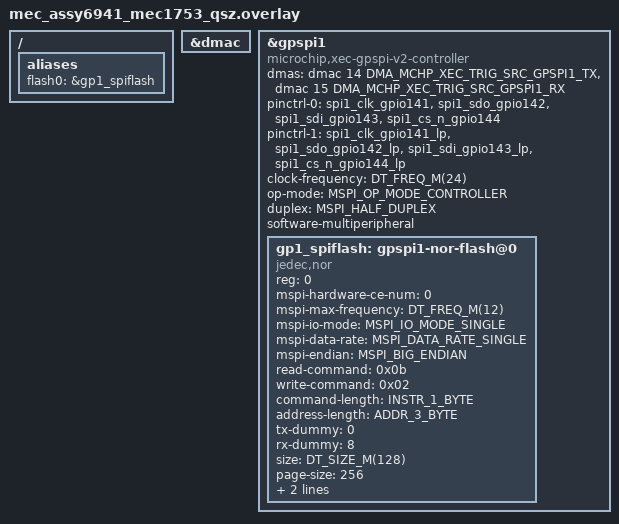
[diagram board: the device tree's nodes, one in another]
/*
 * Copyright (c) 2026 Microchip Technology Inc.
 *
 * SPDX-License-Identifier: Apache-2.0
 */

#include <zephyr/dt-bindings/dma/mchp-xec-dmac.h>

/* mec_assy6941 EVB with MEC1753 daughter card.
 * Winbond 25Q128JVSM +3.3V installed in socket U7
 * U7-5 SPI1_MOSI
 * U7-2 SPI1_MISO
 * U7-6 SPI1_CLK
 * U7-1 SPI1_nCS
 *
 * Jumper block JP20 3x4
 * 2-3 ON choose SPI1_nCS
 * 5-6 ON choose SPI1_MIS0
 * 8-9 ON choose SPI1_CLK
 * 11-12 ON choose SPI1_MOSI
 *
 * Header J37 1x6
 * 1 = VTR1
 * 2 = SPI1_CLK
 * 3 = SPI1_MOSI
 * 4 = SPI1_MISO
 * 5 = SPI1_nCS
 * 6 = GND
 */

/ {
	aliases {
		flash0 = &gp1_spiflash;
	};
};

&dmac {
	status = "okay";
};

&gpspi1 {
	compatible = "microchip,xec-gpspi-v2-controller";
	status = "okay";

	dmas = <&dmac 14 DMA_MCHP_XEC_TRIG_SRC_GPSPI1_TX>,
	       <&dmac 15 DMA_MCHP_XEC_TRIG_SRC_GPSPI1_RX>;
	dma-names = "tx", "rx";

	pinctrl-0 = <&spi1_clk_gpio141 &spi1_sdo_gpio142
		     &spi1_sdi_gpio143 &spi1_cs_n_gpio144>;
	pinctrl-1 = <&spi1_clk_gpio141_lp &spi1_sdo_gpio142_lp
		     &spi1_sdi_gpio143_lp &spi1_cs_n_gpio144_lp>;
	pinctrl-names = "default", "sleep";

	clock-frequency = <DT_FREQ_M(24)>; /* Maximum frequency we allow. HW can do 48MHz */
	op-mode = "MSPI_OP_MODE_CONTROLLER";
	duplex = "MSPI_HALF_DUPLEX";
	software-multiperipheral; /* REQUIRED */

	/* 25Q128JVSM +3.3V
	 * This SPI flash implements single, dual, and quad reads.
	 * For page program it only implements single and quad.
	 * GP-SPI only supports single and dual. Therefore we must
	 * specify single mode here because the MSPI device YAML
	 * binding only has one mspi-io-mode property for all commands.
	 * At the application level we can instantiate separate struct mspi_dev_cfg
	 * for page program 0x02 (1-1-1) and for dual read 0x3B (1-1-2).
	 */
	gp1_spiflash: gpspi1-nor-flash@0 {
		compatible = "jedec,nor";
		reg = <0>;

		mspi-hardware-ce-num = <0>;
		mspi-max-frequency = <DT_FREQ_M(12)>;
		mspi-io-mode = "MSPI_IO_MODE_SINGLE";
		mspi-data-rate = "MSPI_DATA_RATE_SINGLE";
		mspi-endian = "MSPI_BIG_ENDIAN";
		read-command = <0x0b>;
		write-command = <0x02>;
		command-length = "INSTR_1_BYTE";
		address-length = "ADDR_3_BYTE";
		tx-dummy = <0>;
		rx-dummy = <8>;
		size = <DT_SIZE_M(128)>;
		page-size = <256>;
		jedec-id = [ef 70 18];
		sfdp-bfp = [00];
		status = "okay";
	};
};
